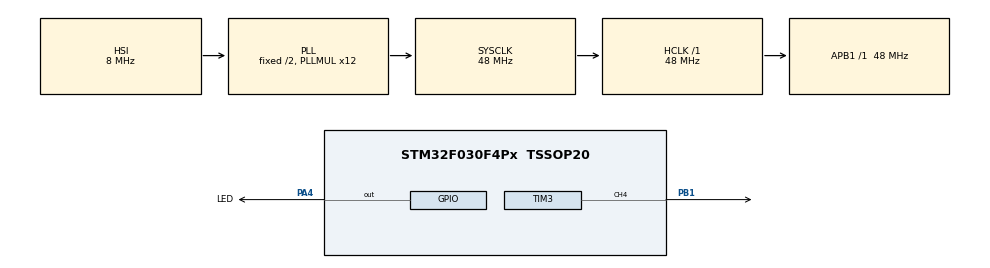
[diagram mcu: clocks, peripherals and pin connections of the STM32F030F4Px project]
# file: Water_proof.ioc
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Mcu.Family=STM32F0
Mcu.Name=STM32F030F4Px
Mcu.Package=TSSOP20
NVIC.RTC_IRQn=true\:0\:0\:false\:false\:true\:true
NVIC.TIM3_IRQn=true\:0\:0\:false\:true\:true\:1\:true
PA0.Mode=SYS_WakeUp0
PA0.Signal=SYS_WKUP1
PA13.Mode=Serial_Wire
PA13.Signal=SYS_SWDIO
PA14.Mode=Serial_Wire
PA14.Signal=SYS_SWCLK
PA4.GPIO_Label=LED
PA4.Signal=GPIO_Output
PB1.Signal=S_TIM3_CH4
ProjectManager.HeapSize=0x200
ProjectManager.StackSize=0x400
ProjectManager.TargetToolchain=MDK-ARM V5
RCC.AHBFreq_Value=48000000
RCC.APB1Freq_Value=48000000
RCC.APB1TimFreq_Value=48000000
RCC.HCLKFreq_Value=48000000
RCC.PLLMUL=RCC_PLL_MUL12
RCC.SYSCLKFreq_VALUE=48000000
RCC.SYSCLKSource=RCC_SYSCLKSOURCE_PLLCLK
RCC.VDD_VALUE=2.4
RTC.Alarm=RTC_ALARM_A
SH.S_TIM3_CH4.0=TIM3_CH4,PWM Generation4 CH4
TIM3.Channel-PWM\ Generation4\ CH4=TIM_CHANNEL_4
TIM3.Period=65534
TIM3.Prescaler=48
TIM3.TIM_MasterSlaveMode=TIM_MASTERSLAVEMODE_DISABLE
VP_RTC_VS_RTC_Activate.Mode=RTC_Enabled
VP_RTC_VS_RTC_Alarm_A_Intern.Mode=Alarm A
VP_RTC_VS_RTC_Calendar.Mode=RTC_Calendar
VP_TIM3_VS_ClockSourceINT.Mode=Internal
board=custom

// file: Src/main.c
/* USER CODE BEGIN Header */
/**
  ******************************************************************************
  * @file           : main.c
  * @brief          : Main program body
  ******************************************************************************
  ** This notice applies to any and all portions of this file
  * that are not between comment pairs USER CODE BEGIN and
  * USER CODE END. Other portions of this file, whether
  * inserted by the user or by software development tools
  * are owned by their respective copyright owners.
  *
  * COPYRIGHT(c) 2019 STMicroelectronics
  *
  * Redistribution and use in source and binary forms, with or without modification,
  * are permitted provided that the following conditions are met:
  *   1. Redistributions of source code must retain the above copyright notice,
  *      this list of conditions and the following disclaimer.
  *   2. Redistributions in binary form must reproduce the above copyright notice,
  *      this list of conditions and the following disclaimer in the documentation
  *      and/or other materials provided with the distribution.
  *   3. Neither the name of STMicroelectronics nor the names of its contributors
  *      may be used to endorse or promote products derived from this software
  *      without specific prior written permission.
  *
  * THIS SOFTWARE IS PROVIDED BY THE COPYRIGHT HOLDERS AND CONTRIBUTORS "AS IS"
  * AND ANY EXPRESS OR IMPLIED WARRANTIES, INCLUDING, BUT NOT LIMITED TO, THE
  * IMPLIED WARRANTIES OF MERCHANTABILITY AND FITNESS FOR A PARTICULAR PURPOSE ARE
  * DISCLAIMED. IN NO EVENT SHALL THE COPYRIGHT HOLDER OR CONTRIBUTORS BE LIABLE
  * FOR ANY DIRECT, INDIRECT, INCIDENTAL, SPECIAL, EXEMPLARY, OR CONSEQUENTIAL
  * DAMAGES (INCLUDING, BUT NOT LIMITED TO, PROCUREMENT OF SUBSTITUTE GOODS OR
  * SERVICES; LOSS OF USE, DATA, OR PROFITS; OR BUSINESS INTERRUPTION) HOWEVER
  * CAUSED AND ON ANY THEORY OF LIABILITY, WHETHER IN CONTRACT, STRICT LIABILITY,
  * OR TORT (INCLUDING NEGLIGENCE OR OTHERWISE) ARISING IN ANY WAY OUT OF THE USE
  * OF THIS SOFTWARE, EVEN IF ADVISED OF THE POSSIBILITY OF SUCH DAMAGE.
  *
  ******************************************************************************
  */
/* USER CODE END Header */

#include "main.h"

/* USER CODE BEGIN PD */

int count=200;

#define C   261 //Do
#define C_  277 //Do#
#define D   293 //Re
#define D_  311 //Re#
#define E   239 //Mi
#define F   349 //Fa
#define F_  370 //Fa#
#define G   392 //Sol
#define G_  415 //Sol#
#define A   440 //La
#define A_  466 //La#
#define H   494 //Si

#define t1      2000
#define t2      1000
#define t4      500
#define t8      250
#define t16     125

typedef struct
{
    uint16_t freq;
    uint16_t time;
}SoundTypeDef;

#define MUSICSIZE 48

const SoundTypeDef Music[MUSICSIZE] ={
    {C*2, t4},
    {G, t4},
    {A_, t8},
    {F, t8},
    {D_, t8},
    {F, t8},
    {G, t4},
    {C, t2},
    {C*2, t4},
    {G, t4},
    {A_, t8},
    {F, t8},
    {D_, t8},
    {F, t8},
    {G, t4},
    {C*2, t4},
    {0, t8},
    {D_, t8},
    {D_, t8},
    {D_, t8},
    {G, t8},
    {A_, t4},
    {D_*2, t8},
    {C_*2, t8},
    {C*2, t8},
    {C*2, t8},
    {C*2, t8},
    {C*2, t8},
    {A_, t8},
    {F, t8},
    {D_, t8},
    {F, t8},
    {G, t4},
    {C*2, t2},
    {C*2, t2},
    {A_, t8},
    {G_, t8},
    {G, t8},
    {G_, t8},
    {A_, t2},
    {A_, t4},
    {C*2, t4},
    {A_, t8},
    {F, t8},
    {D_, t8},
    {F, t8},
    {G, t4},
    {C*2, t2}
};

int MusicStep = 0;
char PlayMusic = 0;

int sound_time;
int sound_counter;

/* USER CODE END PD */

RTC_HandleTypeDef hrtc;

TIM_HandleTypeDef htim3;

void SystemClock_Config(void);
static void MX_GPIO_Init(void);
static void MX_RTC_Init(void);
static void MX_TIM3_Init(void);
static void MX_NVIC_Init(void);
/* USER CODE BEGIN PFP */
void sound (int freq, int time_ms);

/* USER CODE END PFP */

/* USER CODE BEGIN 0 */
/*
void StartMusic(void) {
    MusicStep = 0;
    PlayMusic = 1;
    sound(Music[MusicStep].freq, Music[MusicStep].time);
}
*/
//

/*
void sound (int freq, int time_ms) {
    if (freq > 0) {
        TIM3->ARR = 48000000/ htim3.Init.Prescaler / freq;
        TIM3->CCR1 = TIM3->ARR / 2;
    }
    else {
        TIM3->ARR = 1000;
        TIM3->CCR1 = 0;
    }

		//TIM_SetCounter(TIM3, 0);
		__HAL_TIM_SET_COUNTER(&htim3, 0);//

    sound_time = ((48000000 / htim3.Init.Prescaler / TIM3->ARR) * time_ms ) / 1000;
    sound_counter = 0;
    //TIM_Cmd(TIM3, ENABLE);
		HAL_TIM_Base_Start_IT(&htim3);
		//HAL_TIM_PWM_Start_IT(&htim3);
}
*/

//

/*
void HAL_TIM_PeriodElapsedCallback(TIM_HandleTypeDef *htim)
{

}
*/

/* USER CODE END 0 */

int main(void)
{

  /* MCU Configuration--------------------------------------------------------*/

  /* Reset of all peripherals, Initializes the Flash interface and the Systick. */
  HAL_Init();

  /* Configure the system clock */
  SystemClock_Config();

  /* Initialize all configured peripherals */
  MX_GPIO_Init();
  MX_RTC_Init();
  MX_TIM3_Init();

  /* Initialize interrupts */
  MX_NVIC_Init();
  /* USER CODE BEGIN 2 */

	//START ===========PWM
  //1.  Запускаю базовый таймер 2
  //2.  Запускаю PWM на канале 2 и 3
  //3.  Устанавливаю 0 на выходе канала 2 и 3
  HAL_TIM_Base_Start (&htim3);                  //START TIM2
  HAL_TIM_PWM_Start  (&htim3, TIM_CHANNEL_4);   //START PWM CH2
  //TIM3 ->CCR2 = count;

  /* USER CODE END 2 */

  /* Infinite loop */
  /* USER CODE BEGIN WHILE */
  while (1)
  {
		//sound (440, 1000);
    HAL_Delay(1000);
		HAL_GPIO_TogglePin(LED_GPIO_Port, LED_Pin);
		//htim3.Init.Period = 400
    //__HAL_TIM_SET_COMPARE(&htim3, TIM_CHANNEL_4, count+100);
		//TIM3 ->CCR2 = count+500;;
    //TIM1->ARR = count+100;
    //HAL_TIM_Base_Start(&htim3);                 //START TIM2
    //HAL_TIM_PWM_Start(&htim3, TIM_CHANNEL_4);   //START PWM CH2
    //__HAL_TIM_SET_COUNTER(&htim3, count+100);
    htim3.Init.Period = count+100; //10000 100Hz min;   ;!!!400 2500Hz Rezonance!!!;     200 MAX
    HAL_TIM_PWM_Init(&htim3);
    //__HAL_TIM_SET_COUNTER(&htim3, count+100);//
		if(count>=10000)
		{
      count=200;
		}

    //StartMusic();7

    /* USER CODE END WHILE */

  }
}

void SystemClock_Config(void)
{
  RCC_OscInitTypeDef RCC_OscInitStruct = {0};
  RCC_ClkInitTypeDef RCC_ClkInitStruct = {0};
  RCC_PeriphCLKInitTypeDef PeriphClkInit = {0};

  /**Initializes the CPU, AHB and APB busses clocks
  */
  RCC_OscInitStruct.OscillatorType = RCC_OSCILLATORTYPE_HSI|RCC_OSCILLATORTYPE_LSI;
  RCC_OscInitStruct.HSIState = RCC_HSI_ON;
  RCC_OscInitStruct.HSICalibrationValue = RCC_HSICALIBRATION_DEFAULT;
  RCC_OscInitStruct.LSIState = RCC_LSI_ON;
  RCC_OscInitStruct.PLL.PLLState = RCC_PLL_ON;
  RCC_OscInitStruct.PLL.PLLSource = RCC_PLLSOURCE_HSI;
  RCC_OscInitStruct.PLL.PLLMUL = RCC_PLL_MUL12;
  RCC_OscInitStruct.PLL.PREDIV = RCC_PREDIV_DIV1;
  if (HAL_RCC_OscConfig(&RCC_OscInitStruct) != HAL_OK)
  {
    Error_Handler();
  }
  /**Initializes the CPU, AHB and APB busses clocks
  */
  RCC_ClkInitStruct.ClockType = RCC_CLOCKTYPE_HCLK|RCC_CLOCKTYPE_SYSCLK
                              |RCC_CLOCKTYPE_PCLK1;
  RCC_ClkInitStruct.SYSCLKSource = RCC_SYSCLKSOURCE_PLLCLK;
  RCC_ClkInitStruct.AHBCLKDivider = RCC_SYSCLK_DIV1;
  RCC_ClkInitStruct.APB1CLKDivider = RCC_HCLK_DIV1;

  if (HAL_RCC_ClockConfig(&RCC_ClkInitStruct, FLASH_LATENCY_1) != HAL_OK)
  {
    Error_Handler();
  }
  PeriphClkInit.PeriphClockSelection = RCC_PERIPHCLK_RTC;
  PeriphClkInit.RTCClockSelection = RCC_RTCCLKSOURCE_LSI;
  if (HAL_RCCEx_PeriphCLKConfig(&PeriphClkInit) != HAL_OK)
  {
    Error_Handler();
  }
}

/**
  * @brief NVIC Configuration.
  * @retval None
  */
static void MX_NVIC_Init(void)
{
  /* TIM3_IRQn interrupt configuration */
  HAL_NVIC_SetPriority(TIM3_IRQn, 0, 0);
  HAL_NVIC_EnableIRQ(TIM3_IRQn);
}

static void MX_RTC_Init(void)
{

  RTC_TimeTypeDef sTime = {0};
  RTC_DateTypeDef sDate = {0};
  RTC_AlarmTypeDef sAlarm = {0};

  /**Initialize RTC Only
  */
  hrtc.Instance = RTC;
  hrtc.Init.HourFormat = RTC_HOURFORMAT_24;
  hrtc.Init.AsynchPrediv = 127;
  hrtc.Init.SynchPrediv = 255;
  hrtc.Init.OutPut = RTC_OUTPUT_DISABLE;
  hrtc.Init.OutPutPolarity = RTC_OUTPUT_POLARITY_HIGH;
  hrtc.Init.OutPutType = RTC_OUTPUT_TYPE_OPENDRAIN;
  if (HAL_RTC_Init(&hrtc) != HAL_OK)
  {
    Error_Handler();
  }

  /**Initialize RTC and set the Time and Date
  */
  sTime.Hours = 0x0;
  sTime.Minutes = 0x0;
  sTime.Seconds = 0x0;
  sTime.DayLightSaving = RTC_DAYLIGHTSAVING_NONE;
  sTime.StoreOperation = RTC_STOREOPERATION_RESET;
  if (HAL_RTC_SetTime(&hrtc, &sTime, RTC_FORMAT_BCD) != HAL_OK)
  {
    Error_Handler();
  }
  sDate.WeekDay = RTC_WEEKDAY_MONDAY;
  sDate.Month = RTC_MONTH_JANUARY;
  sDate.Date = 0x1;
  sDate.Year = 0x0;

  if (HAL_RTC_SetDate(&hrtc, &sDate, RTC_FORMAT_BCD) != HAL_OK)
  {
    Error_Handler();
  }
  /**Enable the Alarm A
  */
  sAlarm.AlarmTime.Hours = 0x0;
  sAlarm.AlarmTime.Minutes = 0x0;
  sAlarm.AlarmTime.Seconds = 0x0;
  sAlarm.AlarmTime.SubSeconds = 0x0;
  sAlarm.AlarmTime.DayLightSaving = RTC_DAYLIGHTSAVING_NONE;
  sAlarm.AlarmTime.StoreOperation = RTC_STOREOPERATION_RESET;
  sAlarm.AlarmMask = RTC_ALARMMASK_NONE;
  sAlarm.AlarmSubSecondMask = RTC_ALARMSUBSECONDMASK_ALL;
  sAlarm.AlarmDateWeekDaySel = RTC_ALARMDATEWEEKDAYSEL_DATE;
  sAlarm.AlarmDateWeekDay = 0x1;
  sAlarm.Alarm = RTC_ALARM_A;
  if (HAL_RTC_SetAlarm_IT(&hrtc, &sAlarm, RTC_FORMAT_BCD) != HAL_OK)
  {
    Error_Handler();
  }

}

static void MX_TIM3_Init(void)
{

  TIM_ClockConfigTypeDef sClockSourceConfig = {0};
  TIM_MasterConfigTypeDef sMasterConfig = {0};
  TIM_OC_InitTypeDef sConfigOC = {0};

  htim3.Instance = TIM3;
  htim3.Init.Prescaler = 48; //48 !!!! 1000000Hz
  htim3.Init.CounterMode = TIM_COUNTERMODE_UP;
  htim3.Init.Period = 10000; //10000 100Hz min;   ;!!!400 2500Hz Rezonance!!!;     200 MAX
  htim3.Init.ClockDivision = TIM_CLOCKDIVISION_DIV1;
  htim3.Init.AutoReloadPreload = TIM_AUTORELOAD_PRELOAD_DISABLE;
  if (HAL_TIM_Base_Init(&htim3) != HAL_OK)
  {
    Error_Handler();
  }
  sClockSourceConfig.ClockSource = TIM_CLOCKSOURCE_INTERNAL;
  if (HAL_TIM_ConfigClockSource(&htim3, &sClockSourceConfig) != HAL_OK)
  {
    Error_Handler();
  }
  if (HAL_TIM_PWM_Init(&htim3) != HAL_OK)
  {
    Error_Handler();
  }
  sMasterConfig.MasterOutputTrigger = TIM_TRGO_RESET;
  sMasterConfig.MasterSlaveMode = TIM_MASTERSLAVEMODE_DISABLE;
  if (HAL_TIMEx_MasterConfigSynchronization(&htim3, &sMasterConfig) != HAL_OK)
  {
    Error_Handler();
  }
  sConfigOC.OCMode = TIM_OCMODE_PWM1;
  sConfigOC.Pulse = 200; //Заполнение 50%
  sConfigOC.OCPolarity = TIM_OCPOLARITY_HIGH;
  sConfigOC.OCFastMode = TIM_OCFAST_DISABLE;
  if (HAL_TIM_PWM_ConfigChannel(&htim3, &sConfigOC, TIM_CHANNEL_4) != HAL_OK)
  {
    Error_Handler();
  }
  HAL_TIM_MspPostInit(&htim3);

}

static void MX_GPIO_Init(void)
{
  GPIO_InitTypeDef GPIO_InitStruct = {0};

  /* GPIO Ports Clock Enable */
  __HAL_RCC_GPIOA_CLK_ENABLE();
  __HAL_RCC_GPIOB_CLK_ENABLE();

  /*Configure GPIO pin Output Level */
  HAL_GPIO_WritePin(LED_GPIO_Port, LED_Pin, GPIO_PIN_RESET);

  /*Configure GPIO pin : LED_Pin */
  GPIO_InitStruct.Pin = LED_Pin;
  GPIO_InitStruct.Mode = GPIO_MODE_OUTPUT_PP;
  GPIO_InitStruct.Pull = GPIO_NOPULL;
  GPIO_InitStruct.Speed = GPIO_SPEED_FREQ_LOW;
  HAL_GPIO_Init(LED_GPIO_Port, &GPIO_InitStruct);

}

void Error_Handler(void)
{
}

/************************ (C) COPYRIGHT STMicroelectronics *****END OF FILE****/
